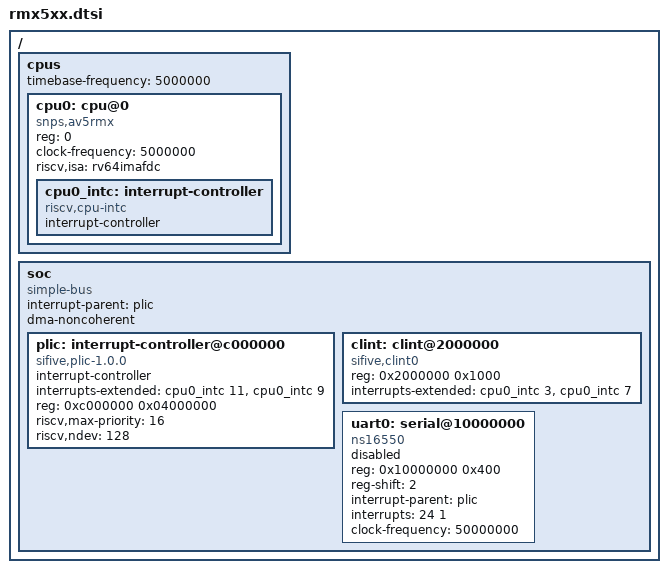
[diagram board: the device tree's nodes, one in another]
/ {
	#address-cells = <1>;
	#size-cells = <1>;

	cpus {
			timebase-frequency = <5000000>;
			#address-cells = <1>;
			#size-cells = <0>;

			cpu0: cpu@0 {
				compatible = "snps,av5rmx", "riscv";
				device_type = "cpu";
				reg = <0>;
				clock-frequency = <5000000>;
//				d-cache-block-size = <64>;
//				d-cache-sets = <256>;
//				d-cache-size = <32768>;
//				i-cache-block-size = <64>;
//				i-cache-sets = <128>;
//				i-cache-size = <32768>;
//				mmu-type = "riscv,sv39";
				riscv,isa = "rv64imafdc";
				#cooling-cells = <2>;

				cpu0_intc: interrupt-controller {
					compatible = "riscv,cpu-intc";
					interrupt-controller;
					#address-cells = <0>;
					#interrupt-cells = <1>;
				};
			};
		};

		soc {
			compatible = "simple-bus";
			ranges;
			interrupt-parent = <&plic>;
			dma-noncoherent;
			#address-cells = <1>;
			#size-cells = <1>;

			plic: interrupt-controller@c000000 {
				compatible = "sifive,plic-1.0.0";
				#interrupt-cells = <2>;
				#address-cells = <1>;
				interrupt-controller;
				interrupts-extended = <&cpu0_intc 11 &cpu0_intc 9>;
				reg = <0xc000000 0x04000000>;
				riscv,max-priority = <16>;
				riscv,ndev = <128>;
			};

			clint: clint@2000000 {
//				compatible = "snps,clint0";
				compatible = "sifive,clint0";
				reg = <0x2000000 0x1000>;
				interrupts-extended = <&cpu0_intc 3 &cpu0_intc 7>;
				interrupt-names = "soft0", "timer0";
			};

			uart0: serial@10000000{
				compatible = "ns16550", "snps,dw-apb-uart";
				reg = <0x10000000 0x400>;
				reg-shift = <2>;
				interrupt-parent = <&plic>;
				interrupts = <24 1>;
				clock-frequency = <50000000>;
				status = "disabled";
			};
		};
};
